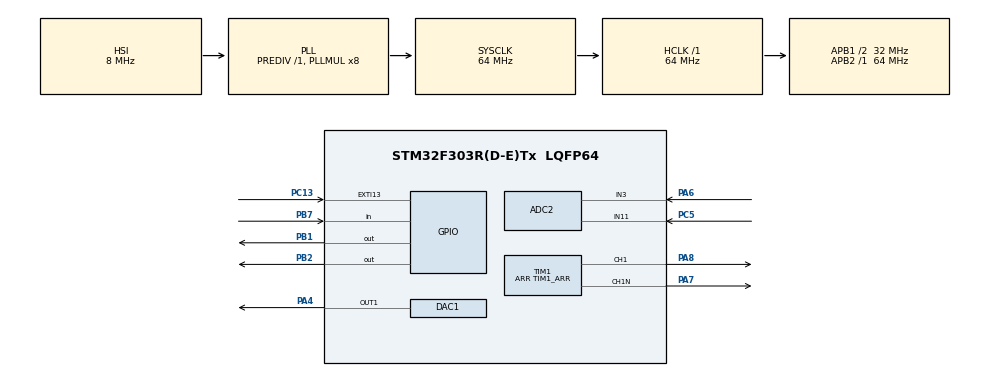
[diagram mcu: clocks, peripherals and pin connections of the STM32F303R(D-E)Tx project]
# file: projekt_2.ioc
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ADC2.Channel-0\#ChannelRegularConversion=ADC_CHANNEL_11
ADC2.Channel-1\#ChannelRegularConversion=ADC_CHANNEL_1
ADC2.Channel-2\#ChannelRegularConversion=ADC_CHANNEL_VREFINT
ADC2.DMAContinuousRequests=ENABLE
ADC2.ExternalTrigConv=ADC_EXTERNALTRIGCONV_T1_CC3
ADC2.NbrOfConversion=3
ADC2.NbrOfConversionFlag=1
ADC2.Offset-0\#ChannelRegularConversion=0
ADC2.Offset-1\#ChannelRegularConversion=0
ADC2.Offset-2\#ChannelRegularConversion=0
ADC2.OffsetNumber-0\#ChannelRegularConversion=ADC_OFFSET_NONE
ADC2.OffsetNumber-1\#ChannelRegularConversion=ADC_OFFSET_NONE
ADC2.OffsetNumber-2\#ChannelRegularConversion=ADC_OFFSET_NONE
ADC2.Rank-0\#ChannelRegularConversion=1
ADC2.Rank-1\#ChannelRegularConversion=2
ADC2.Rank-2\#ChannelRegularConversion=3
ADC2.SamplingTime-0\#ChannelRegularConversion=ADC_SAMPLETIME_19CYCLES_5
ADC2.SamplingTime-1\#ChannelRegularConversion=ADC_SAMPLETIME_19CYCLES_5
ADC2.SamplingTime-2\#ChannelRegularConversion=ADC_SAMPLETIME_181CYCLES_5
Dma.ADC2.0.Direction=DMA_PERIPH_TO_MEMORY
Dma.ADC2.0.Instance=DMA2_Channel1
Dma.ADC2.0.MemDataAlignment=DMA_MDATAALIGN_HALFWORD
Dma.ADC2.0.MemInc=DMA_MINC_ENABLE
Dma.ADC2.0.Mode=DMA_CIRCULAR
Dma.ADC2.0.PeriphDataAlignment=DMA_PDATAALIGN_HALFWORD
Dma.ADC2.0.PeriphInc=DMA_PINC_DISABLE
Dma.ADC2.0.Priority=DMA_PRIORITY_HIGH
Dma.DAC1_CH1.1.Direction=DMA_MEMORY_TO_PERIPH
Dma.DAC1_CH1.1.Instance=DMA1_Channel3
Dma.DAC1_CH1.1.MemDataAlignment=DMA_MDATAALIGN_HALFWORD
Dma.DAC1_CH1.1.MemInc=DMA_MINC_DISABLE
Dma.DAC1_CH1.1.Mode=DMA_CIRCULAR
Dma.DAC1_CH1.1.PeriphDataAlignment=DMA_PDATAALIGN_HALFWORD
Dma.DAC1_CH1.1.PeriphInc=DMA_PINC_DISABLE
Dma.DAC1_CH1.1.Priority=DMA_PRIORITY_MEDIUM
Dma.Request0=ADC2
Dma.Request1=DAC1_CH1
Mcu.Family=STM32F3
Mcu.Name=STM32F303R(D-E)Tx
Mcu.Package=LQFP64
Mcu.UserConstants=TIM1_ARR,63999
NVIC.DMA1_Channel3_IRQn=true\:0\:0\:false\:false\:true\:false\:true
NVIC.DMA2_Channel1_IRQn=true\:0\:0\:false\:false\:true\:false\:true
NVIC.EXTI15_10_IRQn=true\:3\:0\:true\:false\:true\:true\:true
NVIC.PriorityGroup=NVIC_PRIORITYGROUP_4
NVIC.TIM3_IRQn=true\:4\:0\:true\:false\:true\:true\:true
PA13.Mode=Serial_Wire
PA13.Signal=SYS_JTMS-SWDIO
PA14.Mode=Serial_Wire
PA14.Signal=SYS_JTCK-SWCLK
PA4.Signal=SharedAnalog_PA4
PA6.Mode=IN3-Single-Ended
PA6.Signal=ADC2_IN3
PA7.Mode=PWM Generation1 CH1 CH1N
PA7.Signal=TIM1_CH1N
PA8.Signal=S_TIM1_CH1
PB1.Signal=GPIO_Output
PB2.Signal=GPIO_Output
PB7.GPIO_PuPd=GPIO_PULLUP
PB7.Signal=GPIO_Input
PC13.GPIO_PuPd=GPIO_PULLUP
PC13.Signal=GPXTI13
PC5.Mode=IN11-Single-Ended
PC5.Signal=ADC2_IN11
ProjectManager.HeapSize=0x200
ProjectManager.StackSize=0x400
ProjectManager.TargetToolchain=STM32CubeIDE
RCC.AHBFreq_Value=64000000
RCC.APB1CLKDivider=RCC_HCLK_DIV2
RCC.APB1Freq_Value=32000000
RCC.APB1TimFreq_Value=64000000
RCC.APB2Freq_Value=64000000
RCC.APB2TimFreq_Value=64000000
RCC.CortexFreq_Value=64000000
RCC.HCLKFreq_Value=64000000
RCC.HSE_VALUE=8000000
RCC.HSI_VALUE=8000000
RCC.LSE_VALUE=32768
RCC.PLLMUL=RCC_PLL_MUL8
RCC.SYSCLKFreq_VALUE=64000000
RCC.SYSCLKSourceVirtual=RCC_SYSCLKSOURCE_PLLCLK
RCC.USBFreq_Value=64000000
SH.S_TIM1_CH1.0=TIM1_CH1,PWM Generation1 CH1 CH1N
SH.SharedAnalog_PA4.0=DAC1_OUT1,DAC_OUT1
SH.SharedAnalog_PA4.1=ADC2_IN1,IN1-Single-Ended
TIM1.Channel-PWM\ Generation1\ CH1\ CH1N=TIM_CHANNEL_1
TIM1.Channel-PWM\ Generation3\ No\ Output=TIM_CHANNEL_3
TIM1.CounterMode=TIM_COUNTERMODE_CENTERALIGNED1
TIM1.Period=TIM1_ARR
TIM1.Pulse-PWM\ Generation1\ CH1\ CH1N=(TIM1_ARR/2)
TIM1.Pulse-PWM\ Generation3\ No\ Output=(TIM1_ARR/2) - 50
TIM1.TIM_MasterOutputTrigger=TIM_TRGO_UPDATE
TIM3.Period=249
TIM3.Prescaler=63999
VP_ADC2_Vref_Input.Mode=IN-Vrefint
VP_TIM1_VS_ClockSourceINT.Mode=Internal
VP_TIM1_VS_no_output3.Mode=PWM Generation3 No Output
VP_TIM3_VS_ClockSourceINT.Mode=Internal
VP_TIM3_VS_OPM.Mode=OPM_bit
board=custom

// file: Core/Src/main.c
/* USER CODE BEGIN Header */
/**
  ******************************************************************************
  * @file           : main.c
  * @brief          : Main program body
  ******************************************************************************
  * @attention
  *
  * <h2><center>&copy; Copyright (c) 2021 STMicroelectronics.
  * All rights reserved.</center></h2>
  *
  * This software component is licensed by ST under BSD 3-Clause license,
  * the "License"; You may not use this file except in compliance with the
  * License. You may obtain a copy of the License at:
  *                        opensource.org/licenses/BSD-3-Clause
  *
  ******************************************************************************
  */
/* USER CODE END Header */

#include "main.h"

/* USER CODE BEGIN Includes */
#include "mysm.h"
#include "myapp.h"
/* USER CODE END Includes */

void SystemClock_Config(void);
static void MX_GPIO_Init(void);
static void MX_DMA_Init(void);
static void MX_DAC1_Init(void);
static void MX_TIM1_Init(void);
static void MX_ADC2_Init(void);
static void MX_TIM3_Init(void);

int main(void)
{

  /* MCU Configuration--------------------------------------------------------*/

  /* Reset of all peripherals, Initializes the Flash interface and the Systick. */
  HAL_Init();

  /* USER CODE BEGIN Init */
  update_enable_state();
  enabled_state = R_STOP;
  /* USER CODE END Init */

  /* Configure the system clock */
  SystemClock_Config();

  /* Initialize all configured peripherals */
  MX_GPIO_Init();
  MX_DMA_Init();
  MX_DAC1_Init();
  MX_TIM1_Init();
  MX_ADC2_Init();
  MX_TIM3_Init();
  /* USER CODE BEGIN 2 */
  LL_TIM_ClearFlag_UPDATE(TIM3);
  LL_TIM_EnableIT_UPDATE(TIM3);

  LL_TIM_EnableAllOutputs(TIM1);
  LL_TIM_EnableCounter(TIM1);
  LL_TIM_CC_EnableChannel(TIM1, LL_TIM_CHANNEL_CH1 | LL_TIM_CHANNEL_CH3);

  ADC12_COMMON->CCR |= ADC_CCR_TSEN | ADC_CCR_VREFEN;
  hw_init();

  /* USER CODE END 2 */

  /* Infinite loop */
  /* USER CODE BEGIN WHILE */
  while (1)
  {
	state_machine_executor();
    /* USER CODE END WHILE */

  }
}

void SystemClock_Config(void)
{
  RCC_OscInitTypeDef RCC_OscInitStruct = {0};
  RCC_ClkInitTypeDef RCC_ClkInitStruct = {0};
  RCC_PeriphCLKInitTypeDef PeriphClkInit = {0};

  /** Initializes the CPU, AHB and APB busses clocks
  */
  RCC_OscInitStruct.OscillatorType = RCC_OSCILLATORTYPE_HSI;
  RCC_OscInitStruct.HSIState = RCC_HSI_ON;
  RCC_OscInitStruct.HSICalibrationValue = RCC_HSICALIBRATION_DEFAULT;
  RCC_OscInitStruct.PLL.PLLState = RCC_PLL_ON;
  RCC_OscInitStruct.PLL.PLLSource = RCC_PLLSOURCE_HSI;
  RCC_OscInitStruct.PLL.PLLMUL = RCC_PLL_MUL8;
  RCC_OscInitStruct.PLL.PREDIV = RCC_PREDIV_DIV1;
  if (HAL_RCC_OscConfig(&RCC_OscInitStruct) != HAL_OK)
  {
    Error_Handler();
  }
  /** Initializes the CPU, AHB and APB busses clocks
  */
  RCC_ClkInitStruct.ClockType = RCC_CLOCKTYPE_HCLK|RCC_CLOCKTYPE_SYSCLK
                              |RCC_CLOCKTYPE_PCLK1|RCC_CLOCKTYPE_PCLK2;
  RCC_ClkInitStruct.SYSCLKSource = RCC_SYSCLKSOURCE_PLLCLK;
  RCC_ClkInitStruct.AHBCLKDivider = RCC_SYSCLK_DIV1;
  RCC_ClkInitStruct.APB1CLKDivider = RCC_HCLK_DIV2;
  RCC_ClkInitStruct.APB2CLKDivider = RCC_HCLK_DIV1;

  if (HAL_RCC_ClockConfig(&RCC_ClkInitStruct, FLASH_LATENCY_2) != HAL_OK)
  {
    Error_Handler();
  }
  PeriphClkInit.PeriphClockSelection = RCC_PERIPHCLK_TIM1|RCC_PERIPHCLK_ADC12
                              |RCC_PERIPHCLK_TIM34;
  PeriphClkInit.Adc12ClockSelection = RCC_ADC12PLLCLK_DIV1;
  PeriphClkInit.Tim1ClockSelection = RCC_TIM1CLK_HCLK;
  PeriphClkInit.Tim34ClockSelection = RCC_TIM34CLK_HCLK;
  if (HAL_RCCEx_PeriphCLKConfig(&PeriphClkInit) != HAL_OK)
  {
    Error_Handler();
  }
}

static void MX_ADC2_Init(void)
{

  LL_ADC_InitTypeDef ADC_InitStruct = {0};
  LL_ADC_REG_InitTypeDef ADC_REG_InitStruct = {0};

  LL_GPIO_InitTypeDef GPIO_InitStruct = {0};

  /* Peripheral clock enable */
  LL_AHB1_GRP1_EnableClock(LL_AHB1_GRP1_PERIPH_ADC12);

  LL_AHB1_GRP1_EnableClock(LL_AHB1_GRP1_PERIPH_GPIOA);
  LL_AHB1_GRP1_EnableClock(LL_AHB1_GRP1_PERIPH_GPIOC);
  /**ADC2 GPIO Configuration
  PA4   ------> ADC2_IN1
  PA6   ------> ADC2_IN3
  PC5   ------> ADC2_IN11
  */
  GPIO_InitStruct.Pin = LL_GPIO_PIN_4|LL_GPIO_PIN_6;
  GPIO_InitStruct.Mode = LL_GPIO_MODE_ANALOG;
  GPIO_InitStruct.Pull = LL_GPIO_PULL_NO;
  LL_GPIO_Init(GPIOA, &GPIO_InitStruct);

  GPIO_InitStruct.Pin = LL_GPIO_PIN_5;
  GPIO_InitStruct.Mode = LL_GPIO_MODE_ANALOG;
  GPIO_InitStruct.Pull = LL_GPIO_PULL_NO;
  LL_GPIO_Init(GPIOC, &GPIO_InitStruct);

  /* ADC2 DMA Init */

  /* ADC2 Init */
  LL_DMA_SetDataTransferDirection(DMA2, LL_DMA_CHANNEL_1, LL_DMA_DIRECTION_PERIPH_TO_MEMORY);

  LL_DMA_SetChannelPriorityLevel(DMA2, LL_DMA_CHANNEL_1, LL_DMA_PRIORITY_HIGH);

  LL_DMA_SetMode(DMA2, LL_DMA_CHANNEL_1, LL_DMA_MODE_CIRCULAR);

  LL_DMA_SetPeriphIncMode(DMA2, LL_DMA_CHANNEL_1, LL_DMA_PERIPH_NOINCREMENT);

  LL_DMA_SetMemoryIncMode(DMA2, LL_DMA_CHANNEL_1, LL_DMA_MEMORY_INCREMENT);

  LL_DMA_SetPeriphSize(DMA2, LL_DMA_CHANNEL_1, LL_DMA_PDATAALIGN_HALFWORD);

  LL_DMA_SetMemorySize(DMA2, LL_DMA_CHANNEL_1, LL_DMA_MDATAALIGN_HALFWORD);

  /** Common config
  */
  ADC_InitStruct.Resolution = LL_ADC_RESOLUTION_12B;
  ADC_InitStruct.DataAlignment = LL_ADC_DATA_ALIGN_RIGHT;
  ADC_InitStruct.LowPowerMode = LL_ADC_LP_MODE_NONE;
  LL_ADC_Init(ADC2, &ADC_InitStruct);
  ADC_REG_InitStruct.TriggerSource = LL_ADC_REG_TRIG_EXT_TIM1_CH3;
  ADC_REG_InitStruct.SequencerLength = LL_ADC_REG_SEQ_SCAN_ENABLE_3RANKS;
  ADC_REG_InitStruct.SequencerDiscont = LL_ADC_REG_SEQ_DISCONT_DISABLE;
  ADC_REG_InitStruct.ContinuousMode = LL_ADC_REG_CONV_SINGLE;
  ADC_REG_InitStruct.DMATransfer = LL_ADC_REG_DMA_TRANSFER_UNLIMITED;
  ADC_REG_InitStruct.Overrun = LL_ADC_REG_OVR_DATA_OVERWRITTEN;
  LL_ADC_REG_Init(ADC2, &ADC_REG_InitStruct);
  LL_ADC_DisableIT_EOC(ADC2);
  LL_ADC_DisableIT_EOS(ADC2);
  LL_ADC_SetCommonClock(__LL_ADC_COMMON_INSTANCE(ADC2), LL_ADC_CLOCK_ASYNC_DIV1);
  LL_ADC_REG_SetTriggerEdge(ADC2, LL_ADC_REG_TRIG_EXT_RISING);
  /** Configure Regular Channel
  */
  LL_ADC_REG_SetSequencerRanks(ADC2, LL_ADC_REG_RANK_1, LL_ADC_CHANNEL_11);
  LL_ADC_SetChannelSamplingTime(ADC2, LL_ADC_CHANNEL_11, LL_ADC_SAMPLINGTIME_19CYCLES_5);
  LL_ADC_SetChannelSingleDiff(ADC2, LL_ADC_CHANNEL_11, LL_ADC_SINGLE_ENDED);
  /** Configure Regular Channel
  */
  LL_ADC_REG_SetSequencerRanks(ADC2, LL_ADC_REG_RANK_2, LL_ADC_CHANNEL_1);
  LL_ADC_SetChannelSamplingTime(ADC2, LL_ADC_CHANNEL_1, LL_ADC_SAMPLINGTIME_19CYCLES_5);
  LL_ADC_SetChannelSingleDiff(ADC2, LL_ADC_CHANNEL_1, LL_ADC_SINGLE_ENDED);
  /** Configure Regular Channel
  */
  LL_ADC_REG_SetSequencerRanks(ADC2, LL_ADC_REG_RANK_3, LL_ADC_CHANNEL_VREFINT);
  LL_ADC_SetChannelSamplingTime(ADC2, LL_ADC_CHANNEL_VREFINT, LL_ADC_SAMPLINGTIME_181CYCLES_5);
  LL_ADC_SetChannelSingleDiff(ADC2, LL_ADC_CHANNEL_VREFINT, LL_ADC_SINGLE_ENDED);
  LL_ADC_SetCommonPathInternalCh(__LL_ADC_COMMON_INSTANCE(ADC2), LL_ADC_PATH_INTERNAL_VREFINT);

}

static void MX_DAC1_Init(void)
{

  LL_DAC_InitTypeDef DAC_InitStruct = {0};

  LL_GPIO_InitTypeDef GPIO_InitStruct = {0};

  /* Peripheral clock enable */
  LL_APB1_GRP1_EnableClock(LL_APB1_GRP1_PERIPH_DAC1);

  LL_AHB1_GRP1_EnableClock(LL_AHB1_GRP1_PERIPH_GPIOA);
  /**DAC1 GPIO Configuration
  PA4   ------> DAC1_OUT1
  */
  GPIO_InitStruct.Pin = LL_GPIO_PIN_4;
  GPIO_InitStruct.Mode = LL_GPIO_MODE_ANALOG;
  GPIO_InitStruct.Pull = LL_GPIO_PULL_NO;
  LL_GPIO_Init(GPIOA, &GPIO_InitStruct);

  /* DAC1 DMA Init */

  /* DAC1_CH1 Init */
  LL_DMA_SetDataTransferDirection(DMA1, LL_DMA_CHANNEL_3, LL_DMA_DIRECTION_MEMORY_TO_PERIPH);

  LL_DMA_SetChannelPriorityLevel(DMA1, LL_DMA_CHANNEL_3, LL_DMA_PRIORITY_MEDIUM);

  LL_DMA_SetMode(DMA1, LL_DMA_CHANNEL_3, LL_DMA_MODE_CIRCULAR);

  LL_DMA_SetPeriphIncMode(DMA1, LL_DMA_CHANNEL_3, LL_DMA_PERIPH_NOINCREMENT);

  LL_DMA_SetMemoryIncMode(DMA1, LL_DMA_CHANNEL_3, LL_DMA_MEMORY_NOINCREMENT);

  LL_DMA_SetPeriphSize(DMA1, LL_DMA_CHANNEL_3, LL_DMA_PDATAALIGN_HALFWORD);

  LL_DMA_SetMemorySize(DMA1, LL_DMA_CHANNEL_3, LL_DMA_MDATAALIGN_HALFWORD);

  LL_SYSCFG_SetRemapDMA_DAC(LL_SYSCFG_DAC1_CH1_RMP_DMA1_CH3);

  /** DAC channel OUT1 config
  */
  DAC_InitStruct.TriggerSource = LL_DAC_TRIG_SOFTWARE;
  DAC_InitStruct.WaveAutoGeneration = LL_DAC_WAVE_AUTO_GENERATION_NONE;
  DAC_InitStruct.OutputBuffer = LL_DAC_OUTPUT_BUFFER_ENABLE;
  LL_DAC_Init(DAC1, LL_DAC_CHANNEL_1, &DAC_InitStruct);
  LL_DAC_DisableTrigger(DAC1, LL_DAC_CHANNEL_1);

}

static void MX_TIM1_Init(void)
{

  LL_TIM_InitTypeDef TIM_InitStruct = {0};
  LL_TIM_OC_InitTypeDef TIM_OC_InitStruct = {0};
  LL_TIM_BDTR_InitTypeDef TIM_BDTRInitStruct = {0};

  LL_GPIO_InitTypeDef GPIO_InitStruct = {0};

  /* Peripheral clock enable */
  LL_APB2_GRP1_EnableClock(LL_APB2_GRP1_PERIPH_TIM1);

  TIM_InitStruct.Prescaler = 0;
  TIM_InitStruct.CounterMode = LL_TIM_COUNTERMODE_CENTER_UP;
  TIM_InitStruct.Autoreload = TIM1_ARR;
  TIM_InitStruct.ClockDivision = LL_TIM_CLOCKDIVISION_DIV1;
  TIM_InitStruct.RepetitionCounter = 0;
  LL_TIM_Init(TIM1, &TIM_InitStruct);
  LL_TIM_DisableARRPreload(TIM1);
  LL_TIM_SetClockSource(TIM1, LL_TIM_CLOCKSOURCE_INTERNAL);
  LL_TIM_OC_EnablePreload(TIM1, LL_TIM_CHANNEL_CH1);
  TIM_OC_InitStruct.OCMode = LL_TIM_OCMODE_PWM1;
  TIM_OC_InitStruct.OCState = LL_TIM_OCSTATE_DISABLE;
  TIM_OC_InitStruct.OCNState = LL_TIM_OCSTATE_DISABLE;
  TIM_OC_InitStruct.CompareValue = (TIM1_ARR/2);
  TIM_OC_InitStruct.OCPolarity = LL_TIM_OCPOLARITY_HIGH;
  TIM_OC_InitStruct.OCNPolarity = LL_TIM_OCPOLARITY_HIGH;
  TIM_OC_InitStruct.OCIdleState = LL_TIM_OCIDLESTATE_LOW;
  TIM_OC_InitStruct.OCNIdleState = LL_TIM_OCIDLESTATE_LOW;
  LL_TIM_OC_Init(TIM1, LL_TIM_CHANNEL_CH1, &TIM_OC_InitStruct);
  LL_TIM_OC_DisableFast(TIM1, LL_TIM_CHANNEL_CH1);
  LL_TIM_OC_EnablePreload(TIM1, LL_TIM_CHANNEL_CH3);
  TIM_OC_InitStruct.OCState = LL_TIM_OCSTATE_DISABLE;
  TIM_OC_InitStruct.OCNState = LL_TIM_OCSTATE_DISABLE;
  TIM_OC_InitStruct.CompareValue = (TIM1_ARR/2) - 50;
  LL_TIM_OC_Init(TIM1, LL_TIM_CHANNEL_CH3, &TIM_OC_InitStruct);
  LL_TIM_OC_DisableFast(TIM1, LL_TIM_CHANNEL_CH3);
  LL_TIM_SetTriggerOutput(TIM1, LL_TIM_TRGO_UPDATE);
  LL_TIM_SetTriggerOutput2(TIM1, LL_TIM_TRGO2_RESET);
  LL_TIM_DisableMasterSlaveMode(TIM1);
  TIM_BDTRInitStruct.OSSRState = LL_TIM_OSSR_DISABLE;
  TIM_BDTRInitStruct.OSSIState = LL_TIM_OSSI_DISABLE;
  TIM_BDTRInitStruct.LockLevel = LL_TIM_LOCKLEVEL_OFF;
  TIM_BDTRInitStruct.DeadTime = 0;
  TIM_BDTRInitStruct.BreakState = LL_TIM_BREAK_DISABLE;
  TIM_BDTRInitStruct.BreakPolarity = LL_TIM_BREAK_POLARITY_HIGH;
  TIM_BDTRInitStruct.BreakFilter = LL_TIM_BREAK_FILTER_FDIV1;
  TIM_BDTRInitStruct.Break2State = LL_TIM_BREAK2_DISABLE;
  TIM_BDTRInitStruct.Break2Polarity = LL_TIM_BREAK2_POLARITY_HIGH;
  TIM_BDTRInitStruct.Break2Filter = LL_TIM_BREAK2_FILTER_FDIV1;
  TIM_BDTRInitStruct.AutomaticOutput = LL_TIM_AUTOMATICOUTPUT_DISABLE;
  LL_TIM_BDTR_Init(TIM1, &TIM_BDTRInitStruct);
  LL_AHB1_GRP1_EnableClock(LL_AHB1_GRP1_PERIPH_GPIOA);
  /**TIM1 GPIO Configuration
  PA7   ------> TIM1_CH1N
  PA8   ------> TIM1_CH1
  */
  GPIO_InitStruct.Pin = LL_GPIO_PIN_7|LL_GPIO_PIN_8;
  GPIO_InitStruct.Mode = LL_GPIO_MODE_ALTERNATE;
  GPIO_InitStruct.Speed = LL_GPIO_SPEED_FREQ_LOW;
  GPIO_InitStruct.OutputType = LL_GPIO_OUTPUT_PUSHPULL;
  GPIO_InitStruct.Pull = LL_GPIO_PULL_NO;
  GPIO_InitStruct.Alternate = LL_GPIO_AF_6;
  LL_GPIO_Init(GPIOA, &GPIO_InitStruct);

}

static void MX_TIM3_Init(void)
{

  LL_TIM_InitTypeDef TIM_InitStruct = {0};

  /* Peripheral clock enable */
  LL_APB1_GRP1_EnableClock(LL_APB1_GRP1_PERIPH_TIM3);

  /* TIM3 interrupt Init */
  NVIC_SetPriority(TIM3_IRQn, NVIC_EncodePriority(NVIC_GetPriorityGrouping(),4, 0));
  NVIC_EnableIRQ(TIM3_IRQn);

  TIM_InitStruct.Prescaler = 63999;
  TIM_InitStruct.CounterMode = LL_TIM_COUNTERMODE_UP;
  TIM_InitStruct.Autoreload = 249;
  TIM_InitStruct.ClockDivision = LL_TIM_CLOCKDIVISION_DIV1;
  LL_TIM_Init(TIM3, &TIM_InitStruct);
  LL_TIM_DisableARRPreload(TIM3);
  LL_TIM_SetClockSource(TIM3, LL_TIM_CLOCKSOURCE_INTERNAL);
  LL_TIM_SetOnePulseMode(TIM3, LL_TIM_ONEPULSEMODE_SINGLE);
  LL_TIM_SetTriggerOutput(TIM3, LL_TIM_TRGO_RESET);
  LL_TIM_DisableMasterSlaveMode(TIM3);

}

static void MX_DMA_Init(void)
{

  /* Init with LL driver */
  /* DMA controller clock enable */
  LL_AHB1_GRP1_EnableClock(LL_AHB1_GRP1_PERIPH_DMA2);
  LL_AHB1_GRP1_EnableClock(LL_AHB1_GRP1_PERIPH_DMA1);

  /* DMA interrupt init */
  /* DMA1_Channel3_IRQn interrupt configuration */
  NVIC_SetPriority(DMA1_Channel3_IRQn, NVIC_EncodePriority(NVIC_GetPriorityGrouping(),0, 0));
  NVIC_EnableIRQ(DMA1_Channel3_IRQn);
  /* DMA2_Channel1_IRQn interrupt configuration */
  NVIC_SetPriority(DMA2_Channel1_IRQn, NVIC_EncodePriority(NVIC_GetPriorityGrouping(),0, 0));
  NVIC_EnableIRQ(DMA2_Channel1_IRQn);

}

static void MX_GPIO_Init(void)
{
  GPIO_InitTypeDef GPIO_InitStruct = {0};

  /* GPIO Ports Clock Enable */
  __HAL_RCC_GPIOC_CLK_ENABLE();
  __HAL_RCC_GPIOA_CLK_ENABLE();
  __HAL_RCC_GPIOB_CLK_ENABLE();

  /*Configure GPIO pin Output Level */
  HAL_GPIO_WritePin(GPIOB, GPIO_PIN_1|GPIO_PIN_2, GPIO_PIN_RESET);

  /*Configure GPIO pin : PC13 */
  GPIO_InitStruct.Pin = GPIO_PIN_13;
  GPIO_InitStruct.Mode = GPIO_MODE_IT_RISING;
  GPIO_InitStruct.Pull = GPIO_PULLUP;
  HAL_GPIO_Init(GPIOC, &GPIO_InitStruct);

  /*Configure GPIO pins : PB1 PB2 */
  GPIO_InitStruct.Pin = GPIO_PIN_1|GPIO_PIN_2;
  GPIO_InitStruct.Mode = GPIO_MODE_OUTPUT_PP;
  GPIO_InitStruct.Pull = GPIO_NOPULL;
  GPIO_InitStruct.Speed = GPIO_SPEED_FREQ_LOW;
  HAL_GPIO_Init(GPIOB, &GPIO_InitStruct);

  /*Configure GPIO pin : PB7 */
  GPIO_InitStruct.Pin = GPIO_PIN_7;
  GPIO_InitStruct.Mode = GPIO_MODE_INPUT;
  GPIO_InitStruct.Pull = GPIO_PULLUP;
  HAL_GPIO_Init(GPIOB, &GPIO_InitStruct);

  /* EXTI interrupt init*/
  HAL_NVIC_SetPriority(EXTI15_10_IRQn, 3, 0);
  HAL_NVIC_EnableIRQ(EXTI15_10_IRQn);

}

void Error_Handler(void)
{
}

/************************ (C) COPYRIGHT STMicroelectronics *****END OF FILE****/
